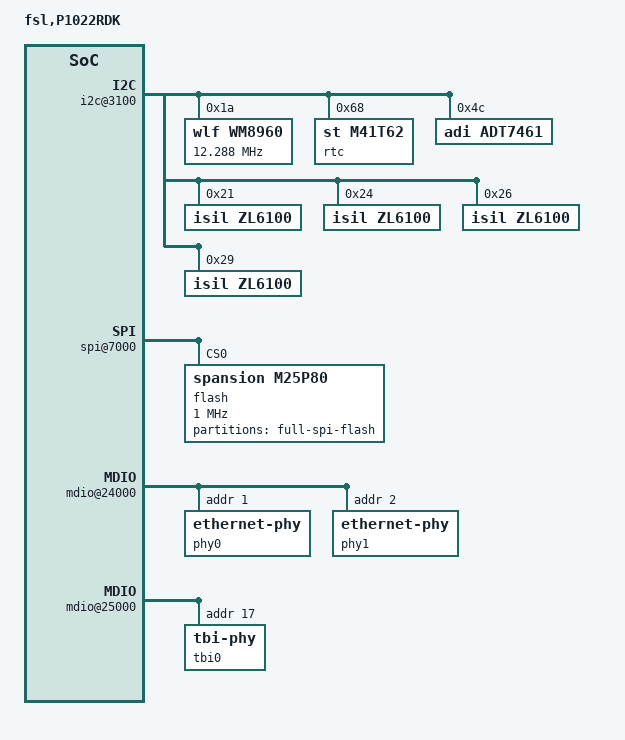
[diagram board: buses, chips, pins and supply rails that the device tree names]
/include/ "p1022si-pre.dtsi"
/ {
	model = "fsl,P1022RDK";
	compatible = "fsl,P1022RDK";
	memory {
		device_type = "memory";
	};
	board_lbc: lbc: localbus@ffe05000 {
		status = "disabled";
	};
	board_soc: soc: soc@ffe00000 {
		ranges = <0x0 0x0 0xffe00000 0x100000>;
		i2c@3100 {
			wm8960:codec@1a {
				compatible = "wlf,wm8960";
				reg = <0x1a>;
				clock-frequency = <12288000>;
			};
			rtc@68 {
				compatible = "st,m41t62";
				reg = <0x68>;
			};
			adt7461@4c {
				compatible = "adi,adt7461";
				reg = <0x4c>;
			};
			zl6100@21 {
				compatible = "isil,zl6100";
				reg = <0x21>;
			};
			zl6100@24 {
				compatible = "isil,zl6100";
				reg = <0x24>;
			};
			zl6100@26 {
				compatible = "isil,zl6100";
				reg = <0x26>;
			};
			zl6100@29 {
				compatible = "isil,zl6100";
				reg = <0x29>;
			};
		};
		spi@7000 {
			flash@0 {
				#address-cells = <1>;
				#size-cells = <1>;
				compatible = "spansion,m25p80", "jedec,spi-nor";
				reg = <0>;
				spi-max-frequency = <1000000>;
				partition@0 {
					label = "full-spi-flash";
					reg = <0x00000000 0x00100000>;
				};
			};
		};
		ssi@15000 {
			fsl,mode = "i2s-slave";
			codec-handle = <&wm8960>;
		};
		usb@22000 {
			phy_type = "ulpi";
		};
		usb@23000 {
			phy_type = "ulpi";
		};
		mdio@24000 {
			phy0: ethernet-phy@0 {
				interrupts = <3 1 0 0>;
				reg = <0x1>;
			};
			phy1: ethernet-phy@1 {
				interrupts = <9 1 0 0>;
				reg = <0x2>;
			};
		};
		mdio@25000 {
			tbi0: tbi-phy@11 {
				reg = <0x11>;
				device_type = "tbi-phy";
			};
		};
		ethernet@b0000 {
			phy-handle = <&phy0>;
			phy-connection-type = "rgmii-id";
		};
		ethernet@b1000 {
			phy-handle = <&phy1>;
			tbi-handle = <&tbi0>;
			phy-connection-type = "sgmii";
		};
	};
	pci0: pcie@ffe09000 {
		ranges = <0x2000000 0x0 0xe0000000 0 0xa0000000 0x0 0x20000000
			  0x1000000 0x0 0x00000000 0 0xffc10000 0x0 0x10000>;
		reg = <0x0 0xffe09000 0 0x1000>;
		pcie@0 {
			ranges = <0x2000000 0x0 0xe0000000
				  0x2000000 0x0 0xe0000000
				  0x0 0x20000000
				  0x1000000 0x0 0x0
				  0x1000000 0x0 0x0
				  0x0 0x100000>;
		};
	};
	pci1: pcie@ffe0a000 {
		ranges = <0x2000000 0x0 0xe0000000 0 0xc0000000 0x0 0x20000000
			  0x1000000 0x0 0x00000000 0 0xffc20000 0x0 0x10000>;
		reg = <0 0xffe0a000 0 0x1000>;
		pcie@0 {
			ranges = <0x2000000 0x0 0xe0000000
				  0x2000000 0x0 0xe0000000
				  0x0 0x20000000
				  0x1000000 0x0 0x0
				  0x1000000 0x0 0x0
				  0x0 0x100000>;
		};
	};
	pci2: pcie@ffe0b000 {
		ranges = <0x2000000 0x0 0xe0000000 0 0x80000000 0x0 0x20000000
			  0x1000000 0x0 0x00000000 0 0xffc00000 0x0 0x10000>;
		reg = <0 0xffe0b000 0 0x1000>;
		pcie@0 {
			ranges = <0x2000000 0x0 0xe0000000
				  0x2000000 0x0 0xe0000000
				  0x0 0x20000000
				  0x1000000 0x0 0x0
				  0x1000000 0x0 0x0
				  0x0 0x100000>;
		};
	};
};
/include/ "p1022si-post.dtsi"
